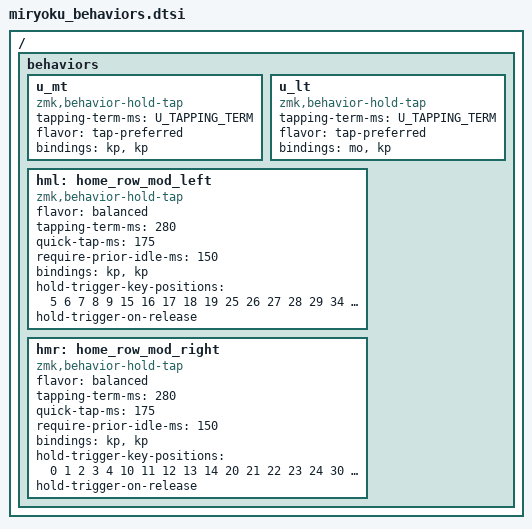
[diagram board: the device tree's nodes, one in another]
// Copyright 2022 Manna Harbour
// https://github.com/manna-harbour/miryoku

/ {
  behaviors {
    u_mt: u_mt {
      compatible = "zmk,behavior-hold-tap";
      #binding-cells = <2>;
      tapping-term-ms = <U_TAPPING_TERM>;
      flavor = "tap-preferred";
      bindings = <&kp>, <&kp>;
    };
    u_lt: u_lt {
      compatible = "zmk,behavior-hold-tap";
      #binding-cells = <2>;
      tapping-term-ms = <U_TAPPING_TERM>;
      flavor = "tap-preferred";
      bindings = <&mo>, <&kp>;
    };
    hml: home_row_mod_left {
      compatible = "zmk,behavior-hold-tap";
      #binding-cells = <2>;
      flavor = "balanced";
      tapping-term-ms = <280>;
      quick-tap-ms = <175>;
      require-prior-idle-ms = <150>;
      bindings = <&kp>, <&kp>;
      hold-trigger-key-positions = <
           5  6  7  8  9
          15 16 17 18 19
          25 26 27 28 29
          34 35 36 37
      >;
      hold-trigger-on-release;
    };
    hmr: home_row_mod_right {
      compatible = "zmk,behavior-hold-tap";
      #binding-cells = <2>;
      flavor = "balanced";
      tapping-term-ms = <280>;
      quick-tap-ms = <175>;
      require-prior-idle-ms = <150>;
      bindings = <&kp>, <&kp>;
      hold-trigger-key-positions = <
           0  1  2  3  4
          10 11 12 13 14
          20 21 22 23 24
          30 31 32 33
      >;
      hold-trigger-on-release;
    };
  };
};
